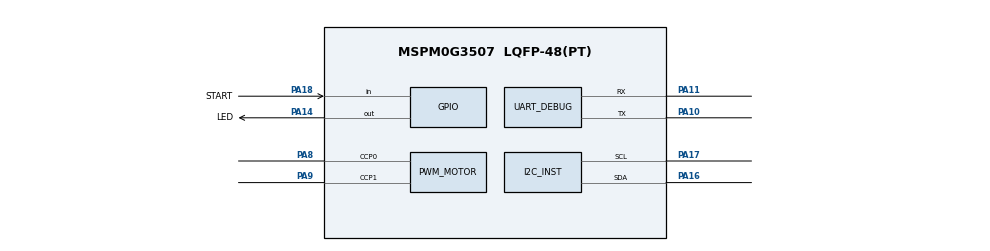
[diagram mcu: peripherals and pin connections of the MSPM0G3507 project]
/**
 * nuedc_car — 完整 SysConfig 配置
 * 芯片：MSPM0G3507 LQFP-48（地猛星开发板）
 *
 * 引脚分配：
 *   PA8  = TIMA0_CCP0 (左电机 PWM)
 *   PA9  = TIMA0_CCP1 (右电机 PWM)
 *   PB2  = AIN1, PB3 = AIN2 (左电机方向)
 *   PB8  = BIN1, PB9 = BIN2 (右电机方向)
 *   PB6  = STBY (TB6612 使能)
 *   PB7  = 蜂鸣器
 *   PA16 = I2C1_SDA, PA17 = I2C1_SCL (MPU6050 + OLED)
 *   PA27~PA24 = ADC0 CH0~CH3, PB17/PB18/PB19 = ADC1 CH4~CH6 (7路灰度)
 *   PA10/PA11 = UART0 (调试串口)
 *   PA14 = LED, PA18 = 按键
 *   PB4/PB5 = 编码器预留 (未启用)
 */

//@cliArgs --device "MSPM0G350X" --package "LQFP-48(PT)" --part "Default"
//@v2CliArgs --device "MSPM0G3507" --package "LQFP-48(PT)"

const Board         = scripting.addModule("/ti/driverlib/Board", {}, false);
const SYSCTL        = scripting.addModule("/ti/driverlib/SYSCTL");
const ProjectConfig = scripting.addModule("/ti/project_config/ProjectConfig");
const GPIO          = scripting.addModule("/ti/driverlib/GPIO", {}, false);
const UART          = scripting.addModule("/ti/driverlib/UART", {}, false);
const PWM           = scripting.addModule("/ti/driverlib/PWM", {}, false);
const I2C           = scripting.addModule("/ti/driverlib/I2C", {}, false);
const ADC12         = scripting.addModule("/ti/driverlib/ADC12", {}, false);

const GPIO_NOTIFY    = GPIO.addInstance();
const GPIO_CONTROL   = GPIO.addInstance();
const GPIO_MOTOR_DIR = GPIO.addInstance();
const GPIO_BUZZER    = GPIO.addInstance();
const UART_DEBUG     = UART.addInstance();
const PWM_MOTOR      = PWM.addInstance();
const I2C_INST       = I2C.addInstance();
const ADC_SENSE      = ADC12.addInstance();
const ADC_SENSE_R    = ADC12.addInstance();

ProjectConfig.deviceSpin = "MSPM0G3507";

/* ========== 时钟 ========== */
SYSCTL.forceDefaultClkConfig = true;
SYSCTL.clockTreeEn = true;
SYSCTL.validateClkStatus = true;

/* ========== 板载 LED (PA14) ========== */
GPIO_NOTIFY.$name = "GPIO_NOTIFY";
GPIO_NOTIFY.port = "PORTA";
GPIO_NOTIFY.portSegment = "Lower";
GPIO_NOTIFY.associatedPins[0].$name = "LED";
GPIO_NOTIFY.associatedPins[0].assignedPort = "PORTA";
GPIO_NOTIFY.associatedPins[0].assignedPortSegment = "Lower";
GPIO_NOTIFY.associatedPins[0].assignedPin = "14";
GPIO_NOTIFY.associatedPins[0].pin.$assign = "PA14";
GPIO_NOTIFY.associatedPins[0].initialValue = "CLEARED";

/* ========== 板载按键 (PA18) ========== */
GPIO_CONTROL.$name = "GPIO_CONTROL";
GPIO_CONTROL.port = "PORTA";
GPIO_CONTROL.portSegment = "Upper";
GPIO_CONTROL.associatedPins[0].$name = "START";
GPIO_CONTROL.associatedPins[0].direction = "INPUT";
GPIO_CONTROL.associatedPins[0].assignedPort = "PORTA";
GPIO_CONTROL.associatedPins[0].assignedPortSegment = "Upper";
GPIO_CONTROL.associatedPins[0].assignedPin = "18";
GPIO_CONTROL.associatedPins[0].pin.$assign = "PA18";

/* ========== 调试串口 UART0 (PA10/PA11) ========== */
UART_DEBUG.$name = "UART_DEBUG";
UART_DEBUG.targetBaudRate = 115200;
UART_DEBUG.enableFIFO = true;
UART_DEBUG.rxFifoThreshold = "DL_UART_RX_FIFO_LEVEL_ONE_ENTRY";
UART_DEBUG.txFifoThreshold = "DL_UART_TX_FIFO_LEVEL_ONE_ENTRY";
UART_DEBUG.enabledInterrupts = ["RX"];
UART_DEBUG.peripheral.$assign = "UART0";
UART_DEBUG.peripheral.txPin.$assign = "PA10";
UART_DEBUG.peripheral.rxPin.$assign = "PA11";

/* ========== 电机 PWM — TIMA0, PA8(C0)/PA9(C1) ========== */
PWM_MOTOR.$name = "PWM_MOTOR";
PWM_MOTOR.peripheral.$assign = "TIMA0";
PWM_MOTOR.peripheral.ccp0Pin.$assign = "PA8";
PWM_MOTOR.peripheral.ccp1Pin.$assign = "PA9";
PWM_MOTOR.timerCount = 1000;
PWM_MOTOR.ccIndex = [0, 1];
PWM_MOTOR.timerStartTimer = true;
PWM_MOTOR.PWM_CHANNEL_0.$name = "ti_driverlib_pwm_PWMTimerCC0";
PWM_MOTOR.PWM_CHANNEL_0.dutyCycle = 0;
PWM_MOTOR.PWM_CHANNEL_1.$name = "ti_driverlib_pwm_PWMTimerCC1";
PWM_MOTOR.PWM_CHANNEL_1.dutyCycle = 0;

/* ========== 电机方向 GPIO — PB2/PB3/PB8/PB9, PB6(STBY) ========== */
GPIO_MOTOR_DIR.$name = "GPIO_MOTOR_DIR";
GPIO_MOTOR_DIR.port = "PORTB";
GPIO_MOTOR_DIR.associatedPins.create(5);
GPIO_MOTOR_DIR.associatedPins[0].$name = "LEFT_AIN1";
GPIO_MOTOR_DIR.associatedPins[0].assignedPort = "PORTB";
GPIO_MOTOR_DIR.associatedPins[0].assignedPin = "2";
GPIO_MOTOR_DIR.associatedPins[0].initialValue = "CLEARED";
GPIO_MOTOR_DIR.associatedPins[1].$name = "LEFT_AIN2";
GPIO_MOTOR_DIR.associatedPins[1].assignedPort = "PORTB";
GPIO_MOTOR_DIR.associatedPins[1].assignedPin = "3";
GPIO_MOTOR_DIR.associatedPins[1].initialValue = "CLEARED";
GPIO_MOTOR_DIR.associatedPins[2].$name = "RIGHT_BIN1";
GPIO_MOTOR_DIR.associatedPins[2].assignedPort = "PORTB";
GPIO_MOTOR_DIR.associatedPins[2].assignedPin = "8";
GPIO_MOTOR_DIR.associatedPins[2].initialValue = "CLEARED";
GPIO_MOTOR_DIR.associatedPins[3].$name = "RIGHT_BIN2";
GPIO_MOTOR_DIR.associatedPins[3].assignedPort = "PORTB";
GPIO_MOTOR_DIR.associatedPins[3].assignedPin = "9";
GPIO_MOTOR_DIR.associatedPins[3].initialValue = "CLEARED";
GPIO_MOTOR_DIR.associatedPins[4].$name = "STBY";
GPIO_MOTOR_DIR.associatedPins[4].assignedPort = "PORTB";
GPIO_MOTOR_DIR.associatedPins[4].assignedPin = "6";
GPIO_MOTOR_DIR.associatedPins[4].initialValue = "SET";

/* ========== 蜂鸣器 (PB7) ========== */
GPIO_BUZZER.$name = "GPIO_BUZZER";
GPIO_BUZZER.port = "PORTB";
GPIO_BUZZER.associatedPins[0].$name = "BUZZ";
GPIO_BUZZER.associatedPins[0].assignedPort = "PORTB";
GPIO_BUZZER.associatedPins[0].assignedPin = "7";
GPIO_BUZZER.associatedPins[0].initialValue = "CLEARED";

/* ========== I2C1 — MPU6050 + OLED (PA16/PA17) ========== */
I2C_INST.$name = "I2C_INST";
I2C_INST.basicEnableController = true;
I2C_INST.basicControllerBusSpeed = 400000;
I2C_INST.peripheral.$assign = "I2C1";
I2C_INST.peripheral.sdaPin.$assign = "PA16";
I2C_INST.peripheral.sclPin.$assign = "PA17";

/* ========== ADC0 — 左/中左 4 路灰度 (PA27~PA24) ========== */
ADC_SENSE.$name = "ADC_SENSE";
ADC_SENSE.samplingOperationMode = "sequence";
ADC_SENSE.endAdd = 3;
ADC_SENSE.sampleTime0 = "12.5us";
ADC_SENSE.adcMem0chansel = "DL_ADC12_INPUT_CHAN_0";
ADC_SENSE.adcMem1chansel = "DL_ADC12_INPUT_CHAN_1";
ADC_SENSE.adcMem2chansel = "DL_ADC12_INPUT_CHAN_2";
ADC_SENSE.adcMem3chansel = "DL_ADC12_INPUT_CHAN_3";
ADC_SENSE.enabledInterrupts = ["DL_ADC12_INTERRUPT_MEM3_RESULT_LOADED"];
ADC_SENSE.peripheral.$assign = "ADC0";
ADC_SENSE.peripheral.adcPin0.$assign = "PA27";
ADC_SENSE.peripheral.adcPin1.$assign = "PA26";
ADC_SENSE.peripheral.adcPin2.$assign = "PA25";
ADC_SENSE.peripheral.adcPin3.$assign = "PA24";

/* ========== ADC1 — 中右/右 3 路灰度 (PB17/PB18/PB19) ========== */
ADC_SENSE_R.$name = "ADC_SENSE_R";
ADC_SENSE_R.samplingOperationMode = "sequence";
ADC_SENSE_R.endAdd = 2;
ADC_SENSE_R.sampleTime0 = "12.5us";
ADC_SENSE_R.adcMem0chansel = "DL_ADC12_INPUT_CHAN_4";
ADC_SENSE_R.adcMem1chansel = "DL_ADC12_INPUT_CHAN_5";
ADC_SENSE_R.adcMem2chansel = "DL_ADC12_INPUT_CHAN_6";
ADC_SENSE_R.enabledInterrupts = ["DL_ADC12_INTERRUPT_MEM2_RESULT_LOADED"];
ADC_SENSE_R.peripheral.$assign = "ADC1";
ADC_SENSE_R.peripheral.adcPin4.$assign = "PB17";
ADC_SENSE_R.peripheral.adcPin5.$assign = "PB18";
ADC_SENSE_R.peripheral.adcPin6.$assign = "PB19";

/*
 * 编码器预留引脚：PB4 (TIMG6_CCP0), PB5 (TIMG6_CCP1)
 * 如需启用，添加 TIMG 实例并配置 QEI 模式。
 */
